# STM32MP13xx register map
File version: 1.5
CPU: CA7 r0p0, little endian, MPU, FPU, 4 interrupt priority bits
Registers are 32-bit, read-write, reset 0x0 unless marked. A register's access mark holds for its fields unless they carry their own. Offsets are from the block's base; [hi:lo] are bit positions; {n}, {i} and the like mark numbered series.

## OTG (part 2 of 3)
Base 0x49000000
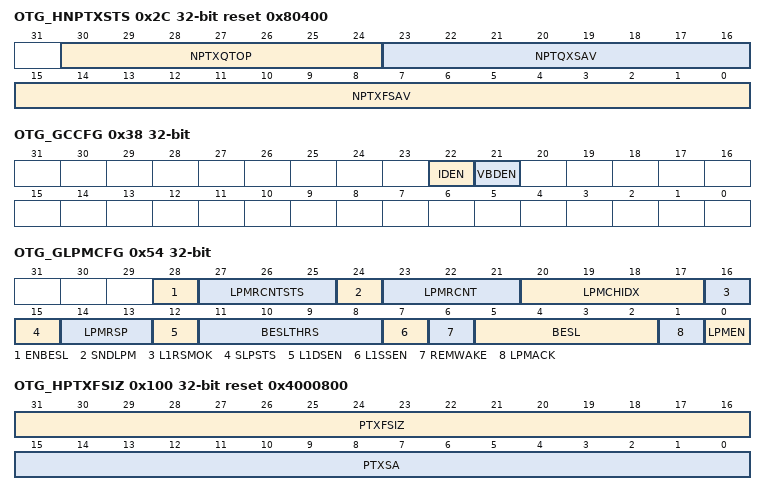
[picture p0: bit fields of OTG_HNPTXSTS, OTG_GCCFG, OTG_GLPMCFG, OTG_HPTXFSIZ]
0x2C OTG_HNPTXSTS ro reset 0x80400 — OTG non-periodic transmit FIFO/queue status register
  [30:24] NPTXQTOP — Top of the non-periodic transmit request queue Entry in the non-periodic Tx request queue that is currently being processed by the MAC. Bits 30:27: Channel/endpoint number Bits 26:25: Bit 24: Terminate (last entry for selected channel/endpoint)
    0=IN/OUT token; 1=Zero-length transmit packet (device IN/host OUT); 3=Channel halt command
  [23:16] NPTQXSAV — Non-periodic transmit request queue space available Indicates the amount of free space available in the non-periodic transmit request queue. This queue holds both IN and OUT requests. 2: locations available n: n locations available (0 â¤ n â¤ 8) Others: Reserved
    0=Non-periodic transmit request queue is full; 1=1 location available
  [15:0] NPTXFSAV — Non-periodic Tx FIFO space available Indicates the amount of free space available in the non-periodic Tx FIFO. Values are in terms of 32-bit words. 2: 2 words available n: n words available (where 0 â¤ n â¤ 512) Others: Reserved
    0=Non-periodic Tx FIFO is full; 1=1 word available
0x38 OTG_GCCFG
  [22] IDEN — USB ID detection enable Enables detection of the ID pin state.
    0=Disable ID pin state detection; 1=Enable ID pin state detection
  [21] VBDEN — USB VBUS detection enable Enables VBUS sensing comparators to detect VBUS valid levels on the VBUS PAD for USB host and device operation. If HNP and/or SRP support is enabled, VBUS comparators are automatically enabled independently of VBDEN value. 0 = VBUS detection disabled 1 = VBUS detection enabled
0x3C OTG_CID reset 0x4000 — OTG core ID register
  [31:0] PRODUCT_ID — Product ID field Application-programmable ID field.
0x54 OTG_GLPMCFG access per field
  [28] ENBESL rw — Enable best effort service latency This bit enables the BESL feature as defined in the LPM errata: USB 2.0 Link Power Management Addendum Engineering Change Notice to the USB 2.0 specification, July 16, 2007 Errata for USB 2.0 ECN: Link Power Management (LPM) - 7/2007 Note: Only the updated behavior (described in LPM Errata) is considered in this document and so the ENBESL bit should be set to '1' by application SW.
    0=The core works as described in the following document:; 1=The core works as described in the LPM Errata:
  [27:25] LPMRCNTSTS ro — LPM retry count status Number of LPM host retries still remaining to be transmitted for the current LPM sequence. Note: Accessible only in host mode.
  [24] SNDLPM rw — Send LPM transaction When the application software sets this bit, an LPM transaction containing two tokens, EXT and LPM is sent. The hardware clears this bit once a valid response (STALL, NYET, or ACK) is received from the device or the core has finished transmitting the programmed number of LPM retries. Note: This bit must be set only when the host is connected to a local port. Note: Accessible only in host mode.
  [23:21] LPMRCNT rw — LPM retry count When the device gives an ERROR response, this is the number of additional LPM retries that the host performs until a valid device response (STALL, NYET, or ACK) is received. Note: Accessible only in host mode.
  [20:17] LPMCHIDX rw — LPM Channel Index The channel number on which the LPM transaction has to be applied while sending an LPM transaction to the local device. Based on the LPM channel index, the core automatically inserts the device address and endpoint number programmed in the corresponding channel into the LPM transaction. Note: Accessible only in host mode.
  [16] L1RSMOK ro — Sleep state resume OK Indicates that the device or host can start resume from Sleep state. This bit is valid in LPM sleep (L1) state. It is set in sleep mode after a delay of 50 Î¼s (TL1Residency). This bit is reset when SLPSTS is 0.
    1=The application or host can start resume from Sleep state; 0=The application or host cannot start resume from Sleep state
  [15] SLPSTS ro — Port sleep status Device mode: This bit is set as long as a Sleep condition is present on the USB bus. The core enters the Sleep state when an ACK response is sent to an LPM transaction and the TL1TokenRetry timer has expired. To stop the PHY clock, the application must set the STPPCLK bit in OTG_PCGCCTL, which asserts the PHY suspend input signal. The application must rely on SLPSTS and not ACK in LPMRSP to confirm transition into sleep. The core comes out of sleep: When there is any activity on the USB linestate When the application writes to the RWUSIG bit in OTG_DCTL or when the application resets or soft-disconnects the device. Host mode: The host transitions to Sleep (L1) state as a side-effect of a successful LPM transaction by the core to the local port with ACK response from the device. The read value of this bit reflects the current Sleep status of the port. The core clears this bit after: The core detects a remote L1 wakeup signal, The application sets the PRST bit or the PRES bit in the OTG_HPRT register, or The application sets the L1Resume/ remote wakeup detected interrupt bit or disconnect detected interrupt bit in the core interrupt register (WKUPINT or DISCINT bit in OTG_GINTSTS, respectively).
    0=Core not in L1; 1=Core in L1
  [14:13] LPMRSP ro — LPM response Device mode: The response of the core to LPM transaction received is reflected in these two bits. Host mode: Handshake response received from local device for LPM transaction
    3=ACK; 2=NYET; 1=STALL; 0=ERROR (No handshake response)
  [12] L1DSEN rw — L1 deep sleep enable Enables suspending the PHY in L1 Sleep mode. For maximum power saving during L1 Sleep mode, this bit should be set to '1' by application SW in all the cases.
  [11:8] BESLTHRS rw — BESL threshold Device mode: The core puts the PHY into deep low power mode in L1 when BESL value is greater than or equal to the value defined in this field BESL_Thres[3:0]. Host mode: The core puts the PHY into deep low power mode in L1. BESLTHRS[3:0] specifies the time for which resume signaling is to be reflected by host (TL1HubDrvResume2) on the USB bus when it detects device initiated resume. BESLTHRS must not be programmed with a value greater than 1100b in host mode, because this exceeds maximum TL1HubDrvResume2. Thres[3:0] host mode resume signaling time (Î¼s): All other values: reserved
    0=75; 1=100; 2=150; 3=250; 4=350; 5=450; 6=950
  [7] L1SSEN rw — L1 Shallow Sleep enable Enables suspending the PHY in L1 Sleep mode. For maximum power saving during L1 Sleep mode, this bit should be set to '1' by application SW in all the cases.
  [6] REMWAKE rw — bRemoteWake value Host mode: The value of remote wake up to be sent in the wIndex field of LPM transaction. Device mode (read-only): This field is updated with the received LPM token bRemoteWake bmAttribute when an ACK, NYET, or STALL response is sent to an LPM transaction.
  [5:2] BESL rw — Best effort service latency Host mode: The value of BESL to be sent in an LPM transaction. This value is also used to initiate resume for a duration TL1HubDrvResume1 for host initiated resume. Device mode (read-only): This field is updated with the received LPM token BESL bmAttribute when an ACK, NYET, or STALL response is sent to an LPM transaction. BESL[3:0] TBESL (Î¼s)
    0=125; 1=150; 2=200; 3=300; 4=400; 5=500; 6=1000; 7=2000; 8=3000; 9=4000; 10=5000; 11=6000; 12=7000; 13=8000; 14=9000; 15=10000
  [1] LPMACK rw — LPM token acknowledge enable Handshake response to LPM token preprogrammed by device application software. Even though ACK is preprogrammed, the core device responds with ACK only on successful LPM transaction. The LPM transaction is successful if: No PID/CRC5 errors in either EXT token or LPM token (else ERROR) Valid bLinkState = 0001B (L1) received in LPM transaction (else STALL) No data pending in transmit queue (else NYET). The preprogrammed software bit is over-ridden for response to LPM token when: The received bLinkState is not L1 (STALL response), or An error is detected in either of the LPM token packets because of corruption (ERROR response). Note: Accessible only in device mode.
    1=ACK; 0=NYET
  [0] LPMEN rw — LPM support enable The application uses this bit to control the OTG core LPM capabilities. If the core operates as a non-LPM-capable host, it cannot request the connected device or hub to activate LPM mode. If the core operates as a non-LPM-capable device, it cannot respond to any LPM transactions.
    0=LPM capability is not enabled; 1=LPM capability is enabled
0x100 OTG_HPTXFSIZ reset 0x4000800
  [31:16] PTXFSIZ — Host periodic Tx FIFO depth This value is in terms of 32-bit words. Minimum value is 16
  [15:0] PTXSA — Host periodic Tx FIFO start address This field configures the memory start address for periodic transmit FIFO RAM.
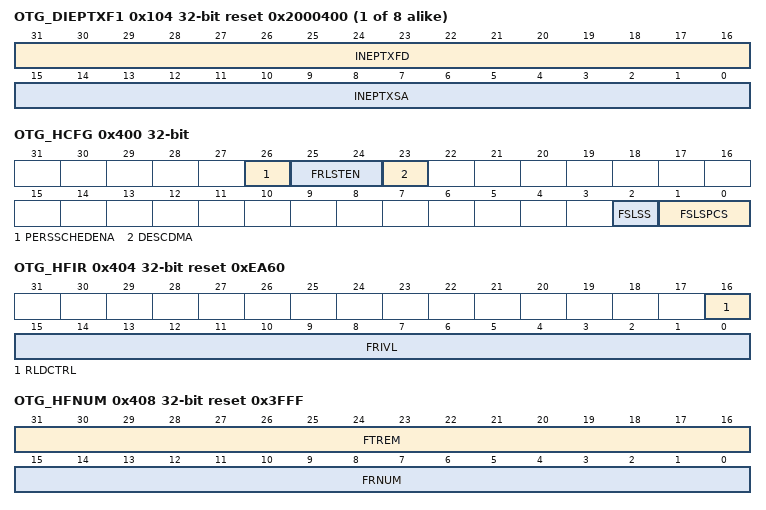
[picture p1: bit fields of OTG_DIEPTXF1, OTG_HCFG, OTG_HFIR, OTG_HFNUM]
{0x100+4i} OTG_DIEPTXF{i} reset 0x2000400 (i=1..8)
  [31:16] INEPTXFD — IN endpoint Tx FIFO depth This value is in terms of 32-bit words. Minimum value is 16
  [15:0] INEPTXSA — IN endpoint FIFOx transmit RAM start address This field contains the memory start address for IN endpoint transmit FIFOx. The address must be aligned with a 32-bit memory location.
0x400 OTG_HCFG access per field — OTG host configuration register
  [26] PERSSCHEDENA rw — Enable periodic scheduling Applicable in host scatter/gather DMA mode only. Enables periodic scheduling within the core. Initially, the bit is res and the core does not process any periodic channels. As soon as this bit is set, the core gets ready to start scheduling periodic channels and sets OTG_HCFG.PERSCHEDSTAT. The setting of PERSCHEDSTAT indicates the core has enabled periodic scheduling. Once PERSSCHEDENA is set, the application is not supposed to reset the bit unless PERSCHEDSTAT is set. As soon as this bit is reset, the core gets ready to stop scheduling periodic channels and resets HCFG. PerSchedStat. In non-Scatter/Gather DMA mode, this bit is reserved.
  [25:24] FRLSTEN rw — Frame list entries The value in the register specifies the number of entries in the Frame list. This field is valid only in Scatter/Gather DMA mode. 2'b00: Reserved 2'b01: 8 Entries 2'b10: 16 Entries 2'b11: 32 Entries In non-Scatter/Gather
  [23] DESCDMA rw — Enable scatter/gather DMA in host mode The application can set this bit during initialization to enable the Scatter/Gather DMA operation. This bit must be modified only once after a reset. The following combinations are available for programming: OTG_GAHBCFG.DMAEN=0,OTG_HCFG.DESCDMA=0 => Slave mode OTG_GAHBCFG.DMAEN=0,OTG_HCFG.DESCDMA=1 => Invalid OTG_GAHBCFG.DMAEN=1,OTG_HCFG.DESCDMA=0 => Buffered DMA mode OTG_GAHBCFG.DMAEN=1,OTG_HCFG.DESCDMA=1 => Scatter/Gather DMA mode
  [2] FSLSS ro — FS- and LS-only support The application uses this bit to control the core's enumeration speed. Using this bit, the application can make the core enumerate as an FS host, even if the connected device supports HS traffic. Do not make changes to this field after initial programming.
  [1:0] FSLSPCS rw — FS/LS PHY clock select Others: Reserved Note: The FSLSPCS must be set on a connection event according to the speed of the connected device (after changing this bit, a software reset must be performed).
    1=B_0x1_CORE_IN_FS_HOST_MODE (PHY clock is running at 48 MHz); 1=B_0x1_CORE_IN_LS_HOST_MODE (Select 48 MHz PHY clock frequency); 2=B_0x2_CORE_IN_LS_HOST_MODE (Select 6 MHz PHY clock frequency)
0x404 OTG_HFIR reset 0xEA60 — OTG host frame interval register
  [16] RLDCTRL — Reload control This bit allows dynamic reloading of the HFIR register during run time. This bit needs to be programmed during initial configuration and its value must not be changed during run time. RLDCTRL = 0 is not recommended.
    0=The HFIR cannot be reloaded dynamically; 1=The HFIR can be dynamically reloaded during run time
  [15:0] FRIVL — Frame interval The value that the application programs to this field, specifies the interval between two consecutive micro-SOFs (HS) or Keep-Alive tokens (LS). This field contains the number of PHY clocks that constitute the required frame interval. The application can write a value to this register only after the port enable bit of the host port control and status register (PENA bit in OTG_HPRT) has been set. If no value is programmed, the core calculates the value based on the PHY clock specified in the FS/LS PHY clock select field of the host configuration register (FSLSPCS in OTG_HCFG). Do not change the value of this field after the initial configuration, unless the RLDCTRL bit is set. In such case, the FRIVL is reloaded with each SOF event. Frame interval = 125Â Î¼s Ã (FRIVL - 1) in high speed operation Frame interval = 1Â ms Ã (FRIVL - 1) in low/full speed operation
0x408 OTG_HFNUM ro reset 0x3FFF — OTG host frame number/frame time remaining register
  [31:16] FTREM — Frame time remaining Indicates the amount of time remaining in the current frame, in terms of PHY clocks. This field decrements on each PHY clock. When it reaches zero, this field is reloaded with the value in the Frame interval register and a new SOF is transmitted on the USB.
  [15:0] FRNUM — Frame number This field increments when a new SOF is transmitted on the USB, and is cleared to 0 when it reaches 0x3FFF.
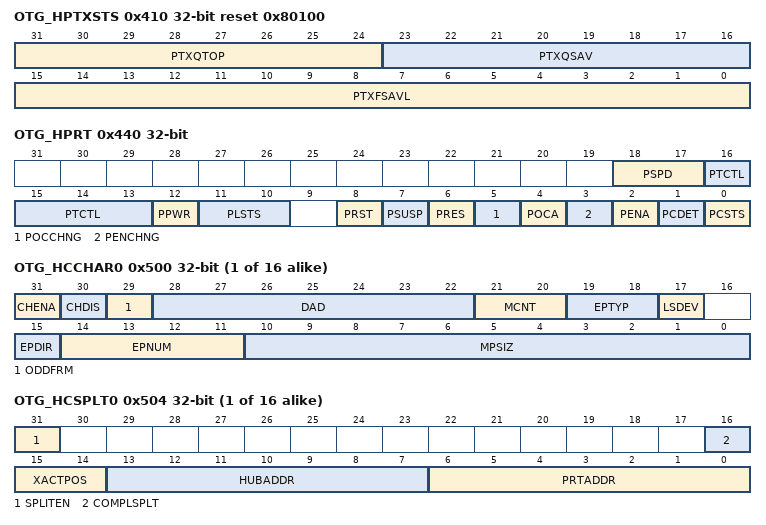
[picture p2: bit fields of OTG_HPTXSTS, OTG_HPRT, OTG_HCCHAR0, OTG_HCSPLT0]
0x410 OTG_HPTXSTS ro reset 0x80100 — OTG_Host periodic transmit FIFO/queue status register
  [31:24] PTXQTOP — Top of the periodic transmit request queue This indicates the entry in the periodic Tx request queue that is currently being processed by the MAC. This register is used for debugging. Bit 31 = 0 send in even frame Bit 31 = 1 send in odd frame Bits 30:27: Channel/endpoint number Bits 26:25 = 00: Type IN/OUT Bits 26:25 = 01: Type Zero-length packet Bits 26:25 = 11: disable channel command Bit 24: Terminate (last entry for the selected channel/endpoint)
  [23:16] PTXQSAV — Periodic transmit request queue space available Indicates the number of free locations available to be written in the periodic transmit request queue. This queue holds both IN and OUT requests. Others: Reserved
    0=Periodic transmit request queue is full; 1=1 location available; 2=2 locations available; 4=3 locations available; 8=4 locations available; 16=5 locations available; 32=6 locations available; 64=7 locations available; 128=8 locations available
  [15:0] PTXFSAVL — Periodic transmit data FIFO space available Indicates the number of free locations available to be written to in the periodic Tx FIFO. Values are in terms of 32-bit words bxn: n words available (where 0 â¤ n â¤ PTXFD) Others: Reserved
    0=Periodic Tx FIFO is full; 1=1 word available; 2=2 words available
0x414 OTG_HAINT ro — OTG host all channels interrupt register
  [15:0] HAINT — Channel interrupts One bit per channel: Bit 0 for Channel 0, bit 15 for Channel 15
0x418 OTG_HAINTMSK — OTG host all channels interrupt mask register
  [15:0] HAINTM — Channel interrupt mask One bit per channel: Bit 0 for channel 0, bit 15 for channel 15
    0=Masked interrupt; 1=Unmasked interrupt
0x41C OTG_HFLBADDR — OTG host frame list base address register
  [31:0] HFLBADDR — The starting address of the frame list (scatter/gather mode). This register is used only for isochronous and interrupt channels.
0x440 OTG_HPRT access per field — OTG host port control and status register
  [18:17] PSPD ro — Port speed Indicates the speed of the device attached to this port.
    1=Full speed; 2=Low speed; 0=High speed
  [16:13] PTCTL rw — Port test control The application writes a nonzero value to this field to put the port into a Test mode, and the corresponding pattern is signaled on the port. Others: Reserved
    0=Test mode disabled; 1=Test_J mode; 2=Test_K mode; 3=Test_SE0_NAK mode; 4=Test_Packet mode; 5=Test_Force_Enable
  [12] PPWR rw — Port power The application uses this field to control power to this port, and the core clears this bit on an overcurrent condition.
    0=Power off; 1=Power on
  [11:10] PLSTS ro — Port line status Indicates the current logic level USB data lines Bit 10: Logic level of OTG_DP Bit 11: Logic level of OTG_DM
  [8] PRST rw — Port reset When the application sets this bit, a reset sequence is started on this port. The application must time the reset period and clear this bit after the reset sequence is complete. The application must leave this bit set for a minimum duration of at least 10Â ms to start a reset on the port. The application can leave it set for another 10 ms in addition to the required minimum duration, before clearing the bit, even though there is no maximum limit set by the USB standard. High speed: 50Â ms Full speed/Low speed: 10Â ms
    0=Port not in reset; 1=Port in reset
  [7] PSUSP rw — Port suspend The application sets this bit to put this port in suspend mode. The core only stops sending SOFs when this is set. To stop the PHY clock, the application must set the port clock stop bit, which asserts the suspend input pin of the PHY. The read value of this bit reflects the current suspend status of the port. This bit is cleared by the core after a remote wakeup signal is detected or the application sets the port reset bit or port resume bit in this register or the resume/remote wakeup detected interrupt bit or disconnect detected interrupt bit in the core interrupt register (WKUPINT or DISCINT in OTG_GINTSTS, respectively).
    0=Port not in suspend mode; 1=Port in suspend mode
  [6] PRES rw — Port resume The application sets this bit to drive resume signaling on the port. The core continues to drive the resume signal until the application clears this bit. If the core detects a USB remote wakeup sequence, as indicated by the port resume/remote wakeup detected interrupt bit of the core interrupt register (WKUPINT bit in OTG_GINTSTS), the core starts driving resume signaling without application intervention and clears this bit when it detects a disconnect condition. The read value of this bit indicates whether the core is currently driving resume signaling. When LPM is enabled and the core is in L1 state, the behavior of this bit is as follow: 1. The application sets this bit to drive resume signaling on the port. 2. The core continues to drive the resume signal until a predetermined time specified in BESLTHRS[3:0] field of OTG_GLPMCFG register. 3. If the core detects a USB remote wakeup sequence, as indicated by the port L1Resume/Remote L1Wakeup detected interrupt bit of the core interrupt register (WKUPINT in OTG_GINTSTS), the core starts driving resume signaling without application intervention and clears this bit at the end of resume.This bit can be set or cleared by both the core and the application. This bit is cleared by the core even if there is no device connected to the host.
    0=No resume driven; 1=Resume driven
  [5] POCCHNG rw — Port overcurrent change The core sets this bit when the status of the port overcurrent active bit (bit 4) in this register changes.
  [4] POCA ro — Port overcurrent active Indicates the overcurrent condition of the port.
    0=No overcurrent condition; 1=Overcurrent condition
  [3] PENCHNG rw — Port enable/disable change The core sets this bit when the status of the port enable bit 2 in this register changes.
  [2] PENA rw — Port enable A port is enabled only by the core after a reset sequence, and is disabled by an overcurrent condition, a disconnect condition, or by the application clearing this bit. The application cannot set this bit by a register write. It can only clear it to disable the port. This bit does not trigger any interrupt to the application.
    0=Port disabled; 1=Port enabled
  [1] PCDET rw — Port connect detected The core sets this bit when a device connection is detected to trigger an interrupt to the application using the host port interrupt bit in the core interrupt register (HPRTINT bit in OTG_GINTSTS). The application must write a 1 to this bit to clear the interrupt.
  [0] PCSTS ro — Port connect status
    0=No device is attached to the port; 1=A device is attached to the port
{0x500+0x20*i} OTG_HCCHAR{i} (i=0..15)
  [31] CHENA — Channel enable When Scatter/Gather mode is enabled: 1'b0: Indicates that the descriptor structure is not yet ready 1'b1: Indicates that the descriptor structure and data buffer with data is setup and this channel can access the descriptor When Scatter/Gather mode is disabled: This field is set by the application and cleared by the OTG host.
    0=Channel disabled; 1=Channel enabled
  [30] CHDIS — Channel disable The application sets this bit to stop transmitting/receiving data on a channel, even before the transfer for that channel is complete. The application must wait for the Channel disabled interrupt before treating the channel as disabled.
  [29] ODDFRM — Odd frame This field is set (reset) by the application to indicate that the OTG host must perform a transfer in an odd frame. This field is applicable for only periodic (isochronous and interrupt) transactions.
    0=Even frame; 1=Odd frame
  [28:22] DAD — Device address This field selects the specific device serving as the data source or sink.
  [21:20] MCNT — Multicount This field indicates to the host the number of transactions that must be executed per frame for this periodic endpoint. For non-periodic transfers, this field is not used Note: This field must be set to at least 01.
    0=Reserved. This field yields undefined results; 1=1 transaction; 2=2 transactions per frame to be issued for this endpoint; 3=3 transactions per frame to be issued for this endpoint
  [19:18] EPTYP — Endpoint type Indicates the transfer type selected.
    0=Control; 1=Isochronous; 2=Bulk; 3=Interrupt
  [17] LSDEV — Low-speed device This field is set by the application to indicate that this channel is communicating to a low-speed device.
  [15] EPDIR — Endpoint direction Indicates whether the transaction is IN or OUT.
    0=OUT; 1=IN
  [14:11] EPNUM — Endpoint number Indicates the endpoint number on the device serving as the data source or sink.
  [10:0] MPSIZ — Maximum packet size Indicates the maximum packet size of the associated endpoint.
{0x504+0x20*i} OTG_HCSPLT{i} (i=0..15)
  [31] SPLITEN — Split enable The application sets this bit to indicate that this channel is enabled to perform split transactions.
  [16] COMPLSPLT — Do complete split The application sets this bit to request the OTG host to perform a complete split transaction.
  [15:14] XACTPOS — Transaction position This field is used to determine whether to send all, first, middle, or last payloads with each OUT transaction.
    3=All. This is the entire data payload of this transaction (which is less than or equal to 188 bytes); 2=Begin. This is the first data payload of this transaction (which is larger than 188 bytes); 0=Mid. This is the middle payload of this transaction (which is larger than 188 bytes); 1=End. This is the last payload of this transaction (which is larger than 188 bytes)
  [13:7] HUBADDR — Hub address This field holds the device address of the transaction translator's hub.
  [6:0] PRTADDR — Port address This field is the port number of the recipient transaction translator.
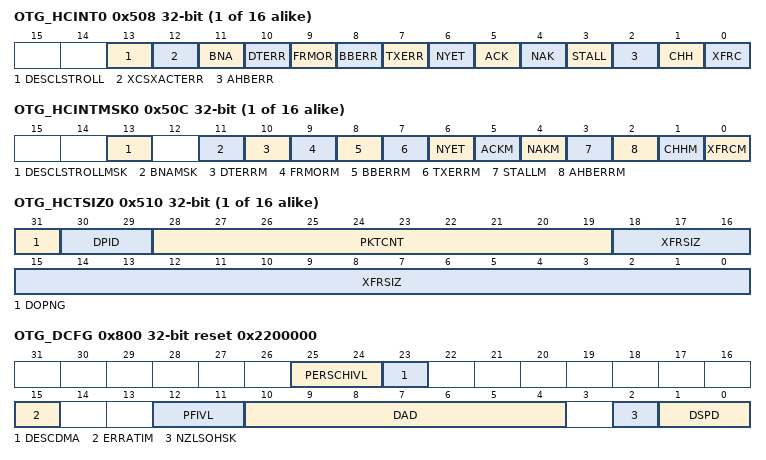
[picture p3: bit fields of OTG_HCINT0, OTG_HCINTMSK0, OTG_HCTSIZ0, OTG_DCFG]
{0x508+0x20*i} OTG_HCINT{i} (i=0..15) — OTG host channel {i} interrupt register
  [13] DESCLSTROLL — Descriptor rollover interrupt. This bit is valid only when Scatter/Gather DMA mode is enabled. The core sets this bit when the corresponding channel descriptor list rolls over. For non Scatter/Gather DMA mode, this bit is reserved.
  [12] XCSXACTERR — Excessive transaction error. This bit is valid only when Scatter/Gather DMA mode is enabled. The core sets this bit when 3 consecutive transaction errors occurred on the USB bus. XCS_XACT_ERR is not generated for isochronous channels. For non Scatter/Gather DMA mode, this bit is reserved.
  [11] BNA — Buffer not available interrupt. This bit is valid only when Scatter/Gather DMA mode is enabled. The core generates this interrupt when the descriptor accessed is not ready for the core to process. BNA interrupt is not generated for isochronous channels. For non Scatter/Gather DMA mode, this bit is reserved.
  [10] DTERR — Data toggle error. In Scatter/Gather DMA mode, the interrupt due to this bit is masked.
  [9] FRMOR — Frame overrun. In Scatter/Gather DMA mode, the interrupt due to this bit is masked.
  [8] BBERR — Babble error. In Scatter/Gather DMA mode, the interrupt due to this bit is masked.
  [7] TXERR — Transaction error. In Scatter/Gather DMA mode, the interrupt due to this bit is masked. Indicates one of the following errors occurred on the USB. CRC check failure Timeout Bit stuff error False EOP
  [6] NYET — Not yet ready response received interrupt. In Scatter/Gather DMA mode, the interrupt due to this bit is masked.
  [5] ACK — ACK response received/transmitted interrupt. In Scatter/Gather DMA mode, the interrupt due to this bit is masked.
  [4] NAK — NAK response received interrupt. In Scatter/Gather DMA mode, the interrupt due to this bit is masked.
  [3] STALL — STALL response received interrupt. In Scatter/Gather DMA mode, the interrupt due to this bit is masked.
  [2] AHBERR — AHB error This error is generated only in Internal DMA mode when an AHB error occurs during an AHB read/write operation. The application can read the corresponding DMA channel address register to get the error address.
  [1] CHH — Channel halted. In non scatter/gather DMA mode indicates the transfer completed abnormally either because of any USB transaction error or in response to disable request by the application. In scatter/gather DMA mode, this indicates that transfer completed due to any of the following: EOL being set in descriptor AHB error Excessive transaction errors In response to disable request by the application Babble Stall
  [0] XFRC — Transfer completed. Transfer completed normally without any errors.
{0x50C+0x20*i} OTG_HCINTMSK{i} (i=0..15) — OTG host channel {i} interrupt mask register
  [13] DESCLSTROLLMSK — Descriptor rollover interrupt mask register. This bit is valid only when Scatter/Gather DMA mode is enabled. In non Scatter/Gather DMA mode, this bit is reserved.
  [11] BNAMSK — Buffer not available interrupt mask register. This bit is valid only when Scatter/Gather DMA mode is enabled. In non Scatter/Gather DMA mode, this bit is reserved
  [10] DTERRM — Data toggle error mask. In Scatter/Gather DMA mode, the interrupt due to this bit is masked.
    0=Masked interrupt; 1=Unmasked interrupt
  [9] FRMORM — Frame overrun mask. In Scatter/Gather DMA mode, the interrupt due to this bit is masked.
    0=Masked interrupt; 1=Unmasked interrupt
  [8] BBERRM — Babble error mask. In Scatter/Gather DMA mode, the interrupt due to this bit is masked.
    0=Masked interrupt; 1=Unmasked interrupt
  [7] TXERRM — Transaction error mask. In Scatter/Gather DMA mode, the interrupt due to this bit is masked.
    0=Masked interrupt; 1=Unmasked interrupt
  [6] NYET — response received interrupt mask. In Scatter/Gather DMA mode, the interrupt due to this bit is masked.
    0=Masked interrupt; 1=Unmasked interrupt
  [5] ACKM — ACK response received/transmitted interrupt mask. In Scatter/Gather DMA mode, the interrupt due to this bit is masked.
    0=Masked interrupt; 1=Unmasked interrupt
  [4] NAKM — NAK response received interrupt mask. In Scatter/Gather DMA mode, the interrupt due to this bit is masked.
    0=Masked interrupt; 1=Unmasked interrupt
  [3] STALLM — STALL response received interrupt mask. In Scatter/Gather DMA mode, the interrupt due to this bit is masked.
    0=Masked interrupt; 1=Unmasked interrupt
  [2] AHBERRM — AHB error. In scatter/gather DMA mode for host, interrupts will not be generated due to the corresponding bits set in OTG_HCINTx.
    0=Masked interrupt; 1=Unmasked interrupt
  [1] CHHM — Channel halted mask
    0=Masked interrupt; 1=Unmasked interrupt
  [0] XFRCM — Transfer completed mask
    0=Masked interrupt; 1=Unmasked interrupt
{0x510+0x20*i} OTG_HCTSIZ{i} (i=0..15)
  [31] DOPNG — Do Ping This bit is used only for OUT transfers. Setting this field to 1 directs the host to do PING protocol. Note: Do not set this bit for IN transfers. If this bit is set for IN transfers, it disables the channel.
  [30:29] DPID — Data PID The application programs this field with the type of PID to use for the initial transaction. The host maintains this field for the rest of the transfer.
    0=DATA0; 1=DATA2; 2=DATA1; 3=SETUP (control) / MDATA (non-control)
  [28:19] PKTCNT — Packet count This field is programmed by the application with the expected number of packets to be transmitted (OUT) or received (IN). The host decrements this count on every successful transmission or reception of an OUT/IN packet. Once this count reaches zero, the application is interrupted to indicate normal completion.
  [18:0] XFRSIZ — Transfer size For an OUT, this field is the number of data bytes the host sends during the transfer. For an IN, this field is the buffer size that the application has reserved for the transfer. The application is expected to program this field as an integer multiple of the maximum packet size for IN transactions (periodic and non-periodic).
{0x514+0x20*i} OTG_HCDMA{i} (i=0..15)
  [31:0] DMAADDR — DMA address This field holds the start address in the external memory from which the data for the endpoint must be fetched or to which it must be stored. This register is incremented on every AHB transaction.
{0x51C+0x20*i} OTG_HCDMAB{i} ro reset not defined (i=0..15)
  [31:0] HCDMAB — DMA address This register holds the current buffer address (scatter/gather mode).
0x800 OTG_DCFG reset 0x2200000 — OTG device configuration register
  [25:24] PERSCHIVL — Periodic schedule interval This field specifies the amount of time the Internal DMA engine must allocate for fetching periodic IN endpoint data. Based on the number of periodic endpoints, this value must be specified as 25, 50 or 75% of the (micro) frame. When any periodic endpoints are active, the internal DMA engine allocates the specified amount of time in fetching periodic IN endpoint data When no periodic endpoint is active, then the internal DMA engine services nonperiodic endpoints, ignoring this field After the specified time within a (micro) frame, the DMA switches to fetching nonperiodic endpoints Note: Periodic Scheduling Interval (PERSCHIVL) must be programmed for Scatter/Gather DMA mode.
    0=25% of (micro)frame; 1=50% of (micro)frame; 2=75% of (micro)frame
  [23] DESCDMA — Enable scatter/gather DMA in device mode The application can set this bit during initialization to enable the Scatter/Gather DMA operation. This bit must be modified only once after a reset. The following combinations are available for programming: OTG_GAHBCFG.DMAEN=0,OTG_DCFG.DESCDMA=0 => Slave mode OTG_GAHBCFG.DMAEN=0,OTG_DCFG.DESCDMA=1 => Invalid OTG_GAHBCFG.DMAEN=1,OTG_DCFG.DESCDMA=0 => Buffer DMA mode OTG_GAHBCFG.DMAEN=1,OTG_DCFG.DESCDMA=1 => Scatter/Gather DMA mode
  [15] ERRATIM — Erratic error interrupt mask
    1=Mask early suspend interrupt on erratic error; 0=Early suspend interrupt is generated on erratic error
  [12:11] PFIVL — Periodic frame interval Indicates the time within a frame at which the application must be notified using the end of periodic frame interrupt. This can be used to determine if all the isochronous traffic for that frame is complete.
    0=80% of the frame interval; 1=85% of the frame interval; 2=90% of the frame interval; 3=95% of the frame interval
  [10:4] DAD — Device address The application must program this field after every SetAddress control command.
  [2] NZLSOHSK — Non-zero-length status OUT handshake The application can use this field to select the handshake the core sends on receiving a nonzero-length data packet during the OUT transaction of a control transfer's status stage.
    1=Send a STALL handshake on a nonzero-length status OUT transaction and do not send the received OUT packet to the application; 0=Send the received OUT packet to the application (zero-length or nonzero-length) and send a handshake based on the NAK and STALL bits for the endpoint in the device endpoint control register
  [1:0] DSPD — Device speed Indicates the speed at which the application requires the core to enumerate, or the maximum speed the application can support. However, the actual bus speed is determined only after the chirp sequence is completed, and is based on the speed of the USB host to which the core is connected.
    0=High speed; 1=Full speed
